# STM32F756ZGY6 register map
File version: 1.0
Registers are 32-bit, access not given, reset 0x0 unless marked. A register's access mark holds for its fields unless they carry their own. Offsets are from the block's base; [hi:lo] are bit positions; {n}, {i} and the like mark numbered series.

## LTDC
Base 0x40016800
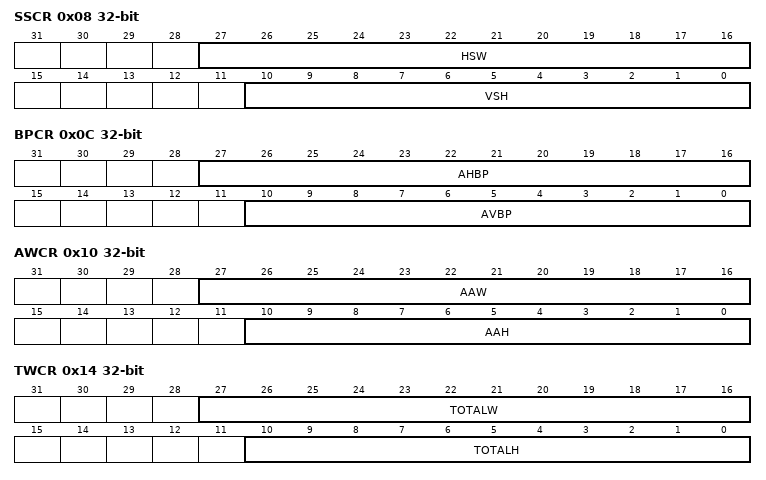
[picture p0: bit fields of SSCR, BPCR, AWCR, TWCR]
0x08 SSCR
  [27:16] HSW, [10:0] VSH
0x0C BPCR
  [27:16] AHBP, [10:0] AVBP
0x10 AWCR
  [27:16] AAW, [10:0] AAH
0x14 TWCR
  [27:16] TOTALW, [10:0] TOTALH
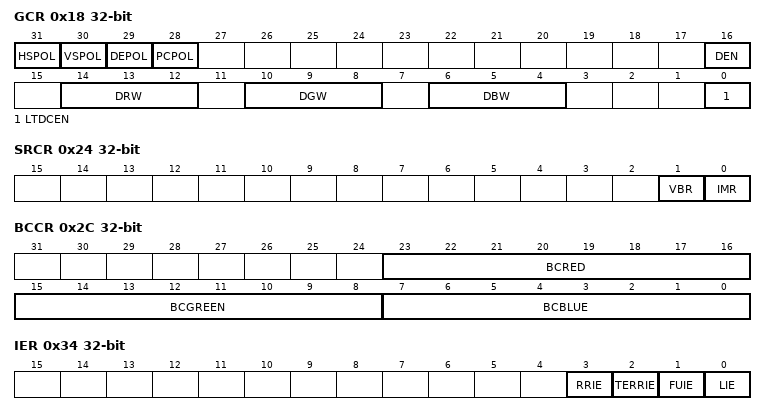
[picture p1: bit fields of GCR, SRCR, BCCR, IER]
0x18 GCR
  [31] HSPOL, [30] VSPOL, [29] DEPOL, [28] PCPOL, [16] DEN, [14:12] DRW, [10:8] DGW, [6:4] DBW, [0] LTDCEN
0x24 SRCR
  [1] VBR, [0] IMR
0x2C BCCR
  [23:16] BCRED, [15:8] BCGREEN, [7:0] BCBLUE
0x34 IER
  [3] RRIE, [2] TERRIE, [1] FUIE, [0] LIE
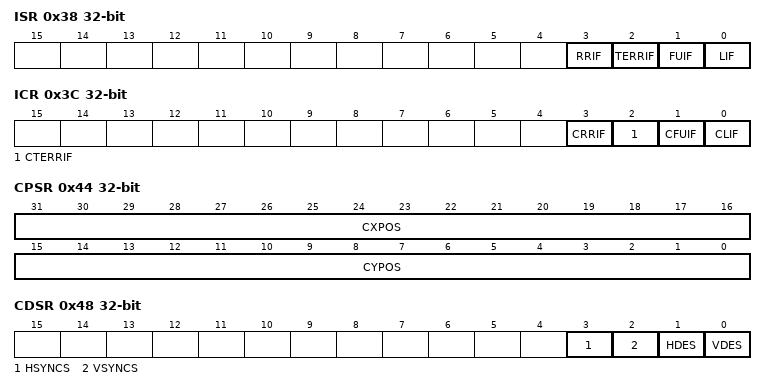
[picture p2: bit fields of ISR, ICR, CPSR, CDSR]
0x38 ISR
  [3] RRIF, [2] TERRIF, [1] FUIF, [0] LIF
0x3C ICR
  [3] CRRIF, [2] CTERRIF, [1] CFUIF, [0] CLIF
0x40 LIPCR
  [10:0] LIPOS
0x44 CPSR
  [31:16] CXPOS, [15:0] CYPOS
0x48 CDSR
  [3] HSYNCS, [2] VSYNCS, [1] HDES, [0] VDES
0x84 CR1
0x88 WHPCR1
0x8C WVPCR1
0x90 CKCR1
0x94 PFCR1
0x98 CACR1
0x9C DCCR1
0xA0 BFCR1
0xAC CFBAR1
0xB0 CFBLR1
0xB4 CFBLNR1
0xC4 CLUTWR1
0x104 CR2
0x108 WHPCR2
0x10C WVPCR2
0x110 CKCR2
0x114 PFCR2
0x118 CACR2
0x11C DCCR2
0x120 BFCR2
0x12C CFBAR2
0x130 CFBLR2
0x134 CFBLNR2
0x144 CLUTWR2

## GPIOA
Base 0x40020000
Same registers: GPIOB 0x40020400, GPIOC 0x40020800, GPIOD 0x40020C00, GPIOE 0x40021000, GPIOF 0x40021400, GPIOG 0x40021800, GPIOH 0x40021C00, GPIOI 0x40022000, GPIOJ 0x40022400, GPIOK 0x40022800
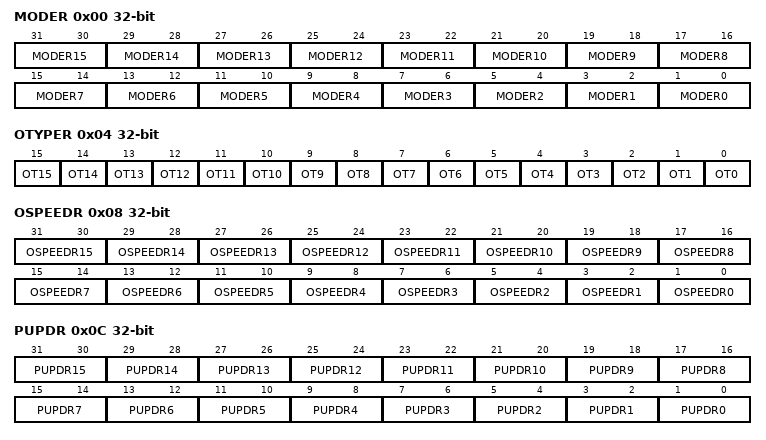
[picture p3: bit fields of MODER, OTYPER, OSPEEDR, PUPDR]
0x00 MODER
  [2n+1:2n] MODER{n} (n=0..15)
0x04 OTYPER
  [n] OT{n} (n=0..15)
0x08 OSPEEDR
  [2n+1:2n] OSPEEDR{n} (n=0..15)
0x0C PUPDR
  [2n+1:2n] PUPDR{n} (n=0..15)
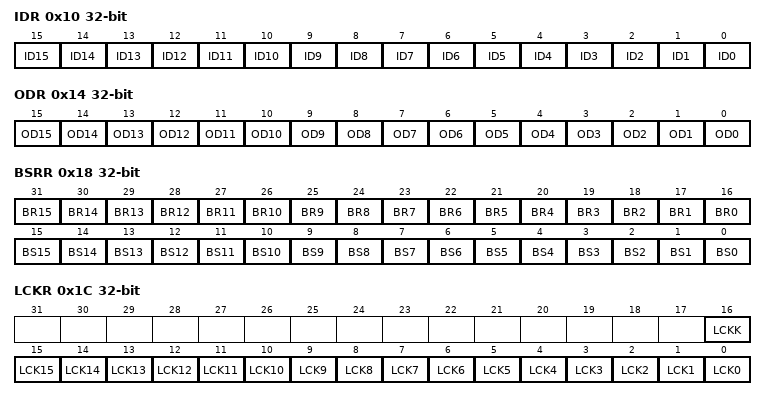
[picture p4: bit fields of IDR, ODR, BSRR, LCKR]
0x10 IDR
  [n] ID{n} (n=0..15)
0x14 ODR
  [n] OD{n} (n=0..15)
0x18 BSRR
  [n+16] BR{n} (n=0..15), [n] BS{n} (n=0..15)
0x1C LCKR
  [16] LCKK, [n] LCK{n} (n=0..15)
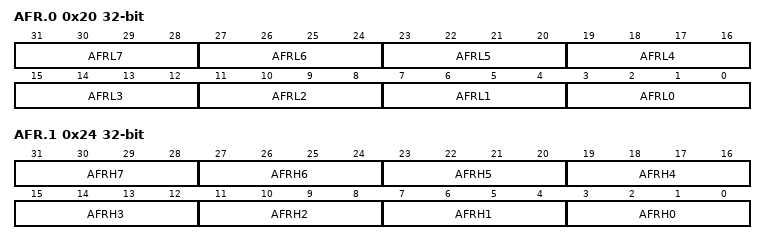
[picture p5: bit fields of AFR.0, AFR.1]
0x20 AFR.0
  [4n+3:4n] AFRL{n} (n=0..7)
0x24 AFR.1
  [4n+3:4n] AFRH{n} (n=0..7)

## CRC
Base 0x40023000
0x00 DR
0x04 IDR 8-bit
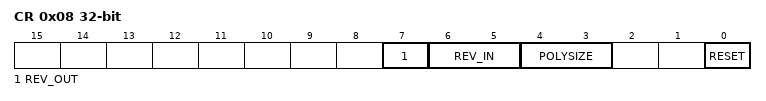
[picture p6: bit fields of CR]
0x08 CR
  [7] REV_OUT, [6:5] REV_IN, [4:3] POLYSIZE, [0] RESET
0x10 INIT
0x14 POL

## FLASH
Base 0x40023C00
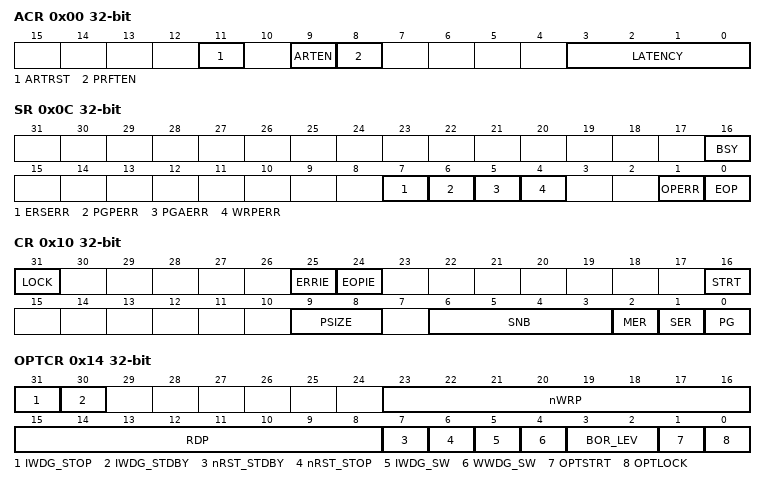
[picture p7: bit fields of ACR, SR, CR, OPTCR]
0x00 ACR
  [11] ARTRST, [9] ARTEN, [8] PRFTEN, [3:0] LATENCY
0x04 KEYR
0x08 OPTKEYR
0x0C SR
  [16] BSY, [7] ERSERR, [6] PGPERR, [5] PGAERR, [4] WRPERR, [1] OPERR, [0] EOP
0x10 CR
  [31] LOCK, [25] ERRIE, [24] EOPIE, [16] STRT, [9:8] PSIZE, [6:3] SNB, [2] MER, [1] SER, [0] PG
0x14 OPTCR
  [31] IWDG_STOP, [30] IWDG_STDBY, [23:16] nWRP, [15:8] RDP, [7] nRST_STDBY, [6] nRST_STOP, [5] IWDG_SW, [4] WWDG_SW, [3:2] BOR_LEV, [1] OPTSTRT, [0] OPTLOCK
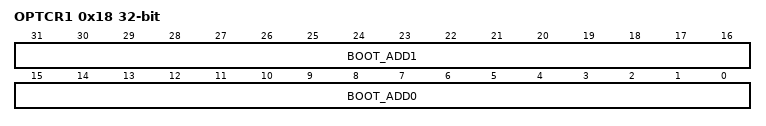
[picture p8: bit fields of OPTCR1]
0x18 OPTCR1
  [31:16] BOOT_ADD1, [15:0] BOOT_ADD0

## DMA1
Base 0x40026000
Same registers: DMA2 0x40026400
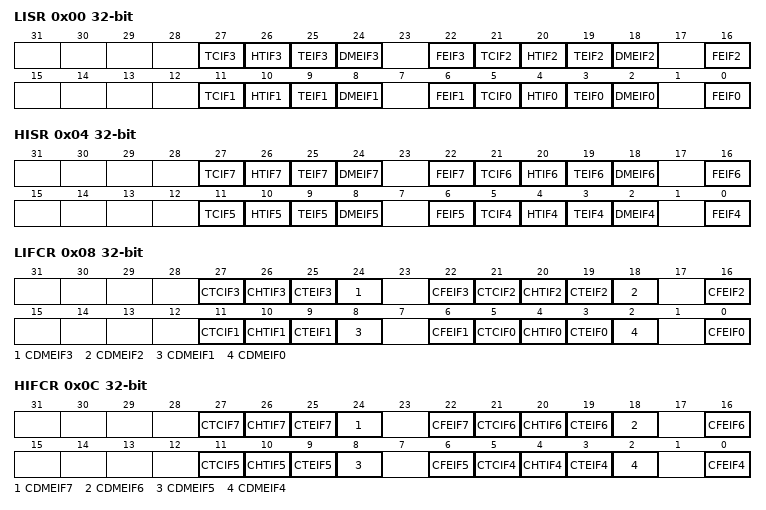
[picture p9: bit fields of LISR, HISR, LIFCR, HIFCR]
0x00 LISR
  [27] TCIF3, [26] HTIF3, [25] TEIF3, [24] DMEIF3, [22] FEIF3, [21] TCIF2, [20] HTIF2, [19] TEIF2, [18] DMEIF2, [16] FEIF2, [11] TCIF1, [10] HTIF1, [9] TEIF1, [8] DMEIF1, [6] FEIF1, [5] TCIF0, [4] HTIF0, [3] TEIF0, [2] DMEIF0, [0] FEIF0
0x04 HISR
  [27] TCIF7, [26] HTIF7, [25] TEIF7, [24] DMEIF7, [22] FEIF7, [21] TCIF6, [20] HTIF6, [19] TEIF6, [18] DMEIF6, [16] FEIF6, [11] TCIF5, [10] HTIF5, [9] TEIF5, [8] DMEIF5, [6] FEIF5, [5] TCIF4, [4] HTIF4, [3] TEIF4, [2] DMEIF4, [0] FEIF4
0x08 LIFCR
  [27] CTCIF3, [26] CHTIF3, [25] CTEIF3, [24] CDMEIF3, [22] CFEIF3, [21] CTCIF2, [20] CHTIF2, [19] CTEIF2, [18] CDMEIF2, [16] CFEIF2, [11] CTCIF1, [10] CHTIF1, [9] CTEIF1, [8] CDMEIF1, [6] CFEIF1, [5] CTCIF0, [4] CHTIF0, [3] CTEIF0, [2] CDMEIF0, [0] CFEIF0
0x0C HIFCR
  [27] CTCIF7, [26] CHTIF7, [25] CTEIF7, [24] CDMEIF7, [22] CFEIF7, [21] CTCIF6, [20] CHTIF6, [19] CTEIF6, [18] CDMEIF6, [16] CFEIF6, [11] CTCIF5, [10] CHTIF5, [9] CTEIF5, [8] CDMEIF5, [6] CFEIF5, [5] CTCIF4, [4] CHTIF4, [3] CTEIF4, [2] CDMEIF4, [0] CFEIF4
{0x10+0x18*i} CR{i} (i=0..7)
{0x14+0x18*i} NDTR{i} (i=0..7)
{0x18+0x18*i} PAR{i} (i=0..7)
{0x1C+0x18*i} M0AR{i} (i=0..7)
{0x20+0x18*i} M1AR{i} (i=0..7)
{0x24+0x18*i} FCR{i} (i=0..7)

## ETH
Base 0x40028000
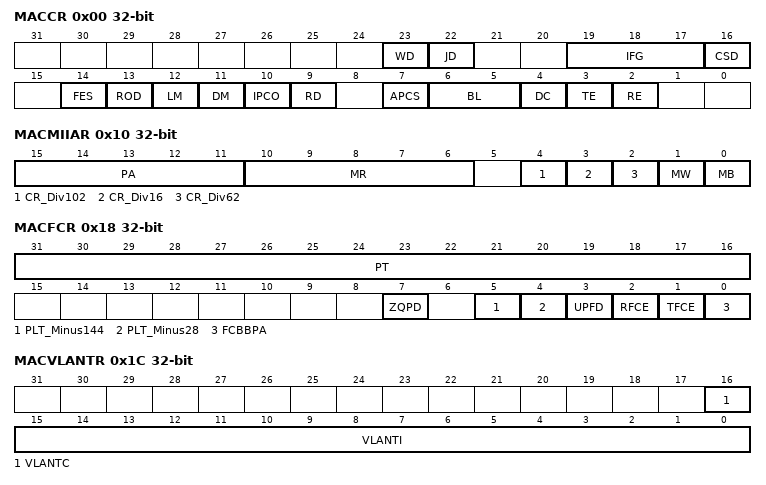
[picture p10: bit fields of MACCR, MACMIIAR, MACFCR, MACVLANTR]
0x00 MACCR
  [23] WD, [22] JD, [19:17] IFG, [16] CSD, [14] FES, [13] ROD, [12] LM, [11] DM, [10] IPCO, [9] RD, [7] APCS, [6:5] BL, [4] DC, [3] TE, [2] RE
0x04 MACFFR
  [31] RA, [10] HPF, [9] SAF, [8] SAIF, [7] PCF_ForwardAll, [7:6] PCF_ForwardPassedAddrFilter, [5] BFD, [4] PAM, [3] DAIF, [2] HM, [1] HU, [0] PM
0x08 MACHTHR
  [31:0] HTH
0x0C MACHTLR
  [31:0] HTL
0x10 MACMIIAR
  [15:11] PA, [10:6] MR, [4] CR_Div102, [3] CR_Div16, [2] CR_Div62, [1] MW, [0] MB
0x14 MACMIIDR
  [15:0] MD
0x18 MACFCR
  [31:16] PT, [7] ZQPD, [5] PLT_Minus144, [4] PLT_Minus28, [3] UPFD, [2] RFCE, [1] TFCE, [0] FCBBPA
0x1C MACVLANTR
  [16] VLANTC, [15:0] VLANTI
0x28 MACRWUFFR
  [31:0] D
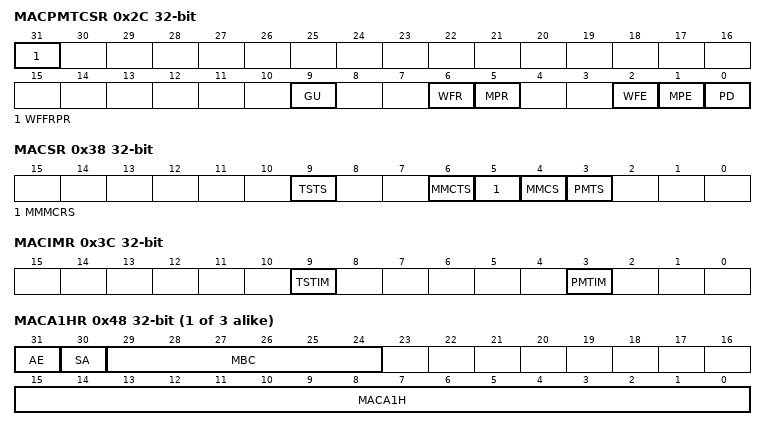
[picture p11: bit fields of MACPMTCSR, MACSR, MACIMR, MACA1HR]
0x2C MACPMTCSR
  [31] WFFRPR, [9] GU, [6] WFR, [5] MPR, [2] WFE, [1] MPE, [0] PD
0x34 MACDBGR
  [25] TFF, [24] TFNE, [22] TPWA, [21] TFRS_WAITING, [21:20] TFRS_WRITING, [19] MTP, [18] MTFCS_GENERATINGPCF, [17] MTFCS_WAITING, [16] MMTEA, [9] RFFL_ABOVEFCT, [9:8] RFFL_FULL, [6] RFRCS_STATUSREADING, [6:5] RFRCS_FLUSHING, [4] RFWRA, [2:1] MSFRWCS, [0] MMRPEA
0x38 MACSR
  [9] TSTS, [6] MMCTS, [5] MMMCRS, [4] MMCS, [3] PMTS
0x3C MACIMR
  [9] TSTIM, [3] PMTIM
0x40 MACA0HR
  [15:0] MACA0H
{0x44+8i} MACA{i}LR (i=0..3)
  [31:0] MACA{i}L
{0x40+8i} MACA{i}HR (i=1..3)
  [31] AE, [30] SA, [29:24] MBC, [15:0] MACA{i}H
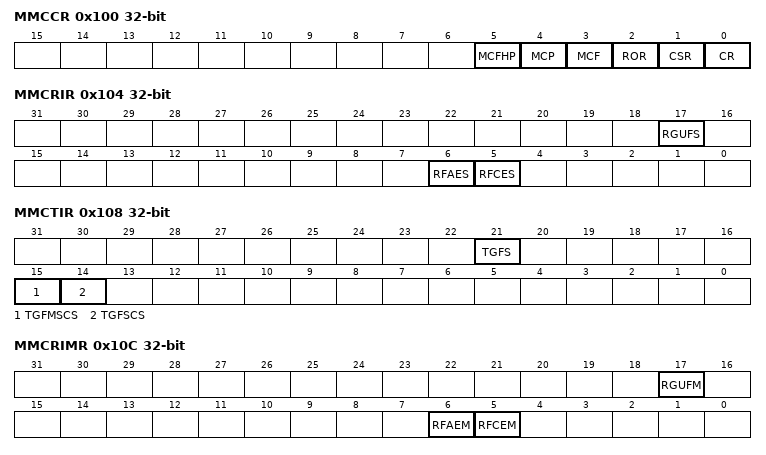
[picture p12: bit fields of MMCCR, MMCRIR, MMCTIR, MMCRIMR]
0x100 MMCCR
  [5] MCFHP, [4] MCP, [3] MCF, [2] ROR, [1] CSR, [0] CR
0x104 MMCRIR
  [17] RGUFS, [6] RFAES, [5] RFCES
0x108 MMCTIR
  [21] TGFS, [15] TGFMSCS, [14] TGFSCS
0x10C MMCRIMR
  [17] RGUFM, [6] RFAEM, [5] RFCEM
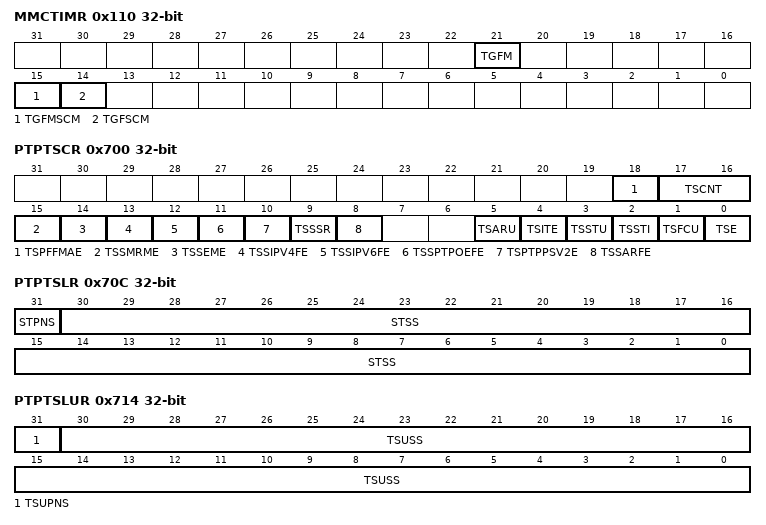
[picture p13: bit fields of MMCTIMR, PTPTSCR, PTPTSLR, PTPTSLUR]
0x110 MMCTIMR
  [21] TGFM, [15] TGFMSCM, [14] TGFSCM
0x14C MMCTGFSCCR
  [31:0] TGFSCC
0x150 MMCTGFMSCCR
  [31:0] TGFMSCC
0x168 MMCTGFCR
  [31:0] TGFC
0x194 MMCRFCECR
  [31:0] RFCEC
0x198 MMCRFAECR
  [31:0] RFAEC
0x1C4 MMCRGUFCR
  [31:0] RGUFC
0x700 PTPTSCR
  [18] TSPFFMAE, [17:16] TSCNT, [15] TSSMRME, [14] TSSEME, [13] TSSIPV4FE, [12] TSSIPV6FE, [11] TSSPTPOEFE, [10] TSPTPPSV2E, [9] TSSSR, [8] TSSARFE, [5] TSARU, [4] TSITE, [3] TSSTU, [2] TSSTI, [1] TSFCU, [0] TSE
0x704 PTPSSIR
  [7:0] STSSI
0x708 PTPTSHR
  [31:0] STS
0x70C PTPTSLR
  [31] STPNS, [30:0] STSS
0x710 PTPTSHUR
  [31:0] TSUS
0x714 PTPTSLUR
  [31] TSUPNS, [30:0] TSUSS
0x718 PTPTSAR
  [31:0] TSA
0x71C PTPTTHR
  [31:0] TTSH
0x720 PTPTTLR
  [31:0] TTSL
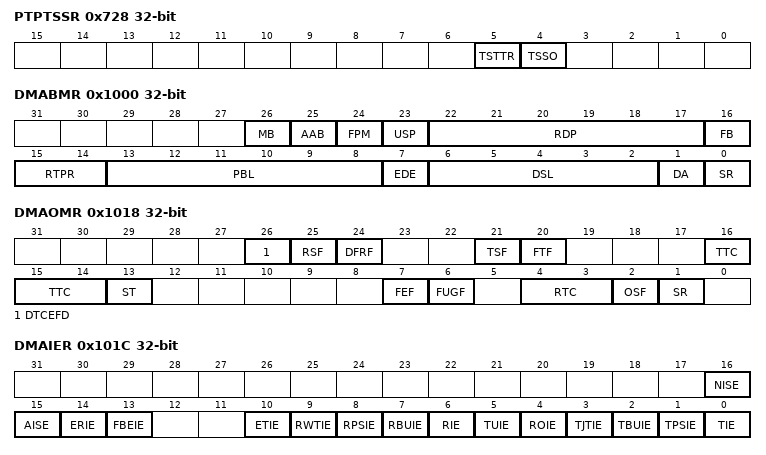
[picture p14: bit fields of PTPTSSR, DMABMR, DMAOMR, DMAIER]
0x728 PTPTSSR
  [5] TSTTR, [4] TSSO
0x72C PTPPPSCR
  [3:0] PPSFREQ
0x1000 DMABMR
  [26] MB, [25] AAB, [24] FPM, [23] USP, [22:17] RDP, [16] FB, [15:14] RTPR, [13:8] PBL, [7] EDE, [6:2] DSL, [1] DA, [0] SR
0x1004 DMATPDR
  [31:0] TPD
0x1008 DMARPDR
  [31:0] RPD
0x100C DMARDLAR
  [31:0] SRL
0x1010 DMATDLAR
  [31:0] STL
0x1014 DMASR
  [29] TSTS, [28] PMTS, [27] MMCS, [25] EBS_DescAccess, [24] EBS_ReadTransf, [23] EBS_DataTransfTx, [21] TPS_Waiting, [21:20] TPS_Reading, [19] RPS_Suspended, [18:17] RPS_Waiting, [16] NIS, [15] AIS, [14] ERS, [13] FBES, [10] ETS, [9] RWTS, [8] RPSS, [7] RBUS, [6] RS, [5] TUS, [4] ROS, [3] TJTS, [2] TBUS, [1] TPSS, [0] TS
0x1018 DMAOMR
  [26] DTCEFD, [25] RSF, [24] DFRF, [21] TSF, [20] FTF, [16:14] TTC, [13] ST, [7] FEF, [6] FUGF, [4:3] RTC, [2] OSF, [1] SR
0x101C DMAIER
  [16] NISE, [15] AISE, [14] ERIE, [13] FBEIE, [10] ETIE, [9] RWTIE, [8] RPSIE, [7] RBUIE, [6] RIE, [5] TUIE, [4] ROIE, [3] TJTIE, [2] TBUIE, [1] TPSIE, [0] TIE
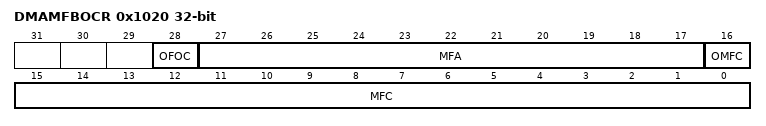
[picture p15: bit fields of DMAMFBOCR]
0x1020 DMAMFBOCR
  [28] OFOC, [27:17] MFA, [16] OMFC, [15:0] MFC
0x1024 DMARSWTR
0x1048 DMACHTDR
  [31:0] HTDAP
0x104C DMACHRDR
  [31:0] HRDAP
0x1050 DMACHTBAR
  [31:0] HTBAP
0x1054 DMACHRBAR
  [31:0] HRBAP
